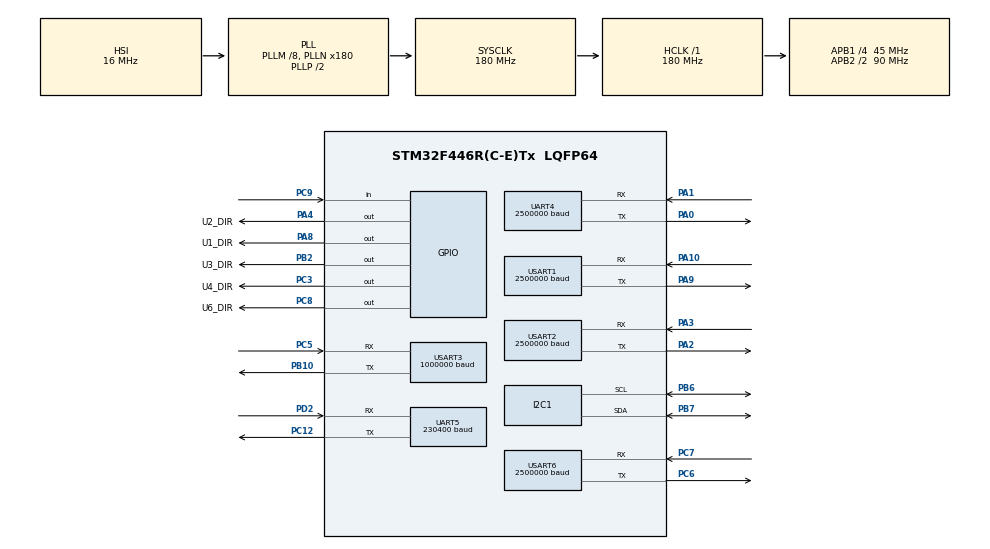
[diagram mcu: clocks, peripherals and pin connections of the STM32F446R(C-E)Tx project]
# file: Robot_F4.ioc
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Dma.Request0=USART3_TX
Dma.Request1=USART3_RX
Dma.Request10=UART4_TX
Dma.Request11=UART4_RX
Dma.Request2=UART5_TX
Dma.Request3=UART5_RX
Dma.Request4=USART2_TX
Dma.Request5=USART2_RX
Dma.Request6=USART1_TX
Dma.Request7=USART1_RX
Dma.Request8=USART6_TX
Dma.Request9=USART6_RX
Dma.UART4_RX.11.Direction=DMA_PERIPH_TO_MEMORY
Dma.UART4_RX.11.FIFOMode=DMA_FIFOMODE_DISABLE
Dma.UART4_RX.11.Instance=DMA1_Stream2
Dma.UART4_RX.11.MemDataAlignment=DMA_MDATAALIGN_BYTE
Dma.UART4_RX.11.MemInc=DMA_MINC_ENABLE
Dma.UART4_RX.11.Mode=DMA_NORMAL
Dma.UART4_RX.11.PeriphDataAlignment=DMA_PDATAALIGN_BYTE
Dma.UART4_RX.11.PeriphInc=DMA_PINC_DISABLE
Dma.UART4_RX.11.Priority=DMA_PRIORITY_LOW
Dma.UART4_TX.10.Direction=DMA_MEMORY_TO_PERIPH
Dma.UART4_TX.10.FIFOMode=DMA_FIFOMODE_DISABLE
Dma.UART4_TX.10.Instance=DMA1_Stream4
Dma.UART4_TX.10.MemDataAlignment=DMA_MDATAALIGN_BYTE
Dma.UART4_TX.10.MemInc=DMA_MINC_ENABLE
Dma.UART4_TX.10.Mode=DMA_NORMAL
Dma.UART4_TX.10.PeriphDataAlignment=DMA_PDATAALIGN_BYTE
Dma.UART4_TX.10.PeriphInc=DMA_PINC_DISABLE
Dma.UART4_TX.10.Priority=DMA_PRIORITY_LOW
Dma.UART5_RX.3.Direction=DMA_PERIPH_TO_MEMORY
Dma.UART5_RX.3.FIFOMode=DMA_FIFOMODE_DISABLE
Dma.UART5_RX.3.Instance=DMA1_Stream0
Dma.UART5_RX.3.MemDataAlignment=DMA_MDATAALIGN_BYTE
Dma.UART5_RX.3.MemInc=DMA_MINC_ENABLE
Dma.UART5_RX.3.Mode=DMA_CIRCULAR
Dma.UART5_RX.3.PeriphDataAlignment=DMA_PDATAALIGN_BYTE
Dma.UART5_RX.3.PeriphInc=DMA_PINC_DISABLE
Dma.UART5_RX.3.Priority=DMA_PRIORITY_LOW
Dma.UART5_TX.2.Direction=DMA_MEMORY_TO_PERIPH
Dma.UART5_TX.2.FIFOMode=DMA_FIFOMODE_DISABLE
Dma.UART5_TX.2.Instance=DMA1_Stream7
Dma.UART5_TX.2.MemDataAlignment=DMA_MDATAALIGN_BYTE
Dma.UART5_TX.2.MemInc=DMA_MINC_ENABLE
Dma.UART5_TX.2.Mode=DMA_NORMAL
Dma.UART5_TX.2.PeriphDataAlignment=DMA_PDATAALIGN_BYTE
Dma.UART5_TX.2.PeriphInc=DMA_PINC_DISABLE
Dma.UART5_TX.2.Priority=DMA_PRIORITY_LOW
Dma.USART1_RX.7.Direction=DMA_PERIPH_TO_MEMORY
Dma.USART1_RX.7.FIFOMode=DMA_FIFOMODE_DISABLE
Dma.USART1_RX.7.Instance=DMA2_Stream2
Dma.USART1_RX.7.MemDataAlignment=DMA_MDATAALIGN_BYTE
Dma.USART1_RX.7.MemInc=DMA_MINC_ENABLE
Dma.USART1_RX.7.Mode=DMA_NORMAL
Dma.USART1_RX.7.PeriphDataAlignment=DMA_PDATAALIGN_BYTE
Dma.USART1_RX.7.PeriphInc=DMA_PINC_DISABLE
Dma.USART1_RX.7.Priority=DMA_PRIORITY_LOW
Dma.USART1_TX.6.Direction=DMA_MEMORY_TO_PERIPH
Dma.USART1_TX.6.FIFOMode=DMA_FIFOMODE_DISABLE
Dma.USART1_TX.6.Instance=DMA2_Stream7
Dma.USART1_TX.6.MemDataAlignment=DMA_MDATAALIGN_BYTE
Dma.USART1_TX.6.MemInc=DMA_MINC_ENABLE
Dma.USART1_TX.6.Mode=DMA_NORMAL
Dma.USART1_TX.6.PeriphDataAlignment=DMA_PDATAALIGN_BYTE
Dma.USART1_TX.6.PeriphInc=DMA_PINC_DISABLE
Dma.USART1_TX.6.Priority=DMA_PRIORITY_LOW
Dma.USART2_RX.5.Direction=DMA_PERIPH_TO_MEMORY
Dma.USART2_RX.5.FIFOMode=DMA_FIFOMODE_DISABLE
Dma.USART2_RX.5.Instance=DMA1_Stream5
Dma.USART2_RX.5.MemDataAlignment=DMA_MDATAALIGN_BYTE
Dma.USART2_RX.5.MemInc=DMA_MINC_ENABLE
Dma.USART2_RX.5.Mode=DMA_NORMAL
Dma.USART2_RX.5.PeriphDataAlignment=DMA_PDATAALIGN_BYTE
Dma.USART2_RX.5.PeriphInc=DMA_PINC_DISABLE
Dma.USART2_RX.5.Priority=DMA_PRIORITY_LOW
Dma.USART2_TX.4.Direction=DMA_MEMORY_TO_PERIPH
Dma.USART2_TX.4.FIFOMode=DMA_FIFOMODE_DISABLE
Dma.USART2_TX.4.Instance=DMA1_Stream6
Dma.USART2_TX.4.MemDataAlignment=DMA_MDATAALIGN_BYTE
Dma.USART2_TX.4.MemInc=DMA_MINC_ENABLE
Dma.USART2_TX.4.Mode=DMA_NORMAL
Dma.USART2_TX.4.PeriphDataAlignment=DMA_PDATAALIGN_BYTE
Dma.USART2_TX.4.PeriphInc=DMA_PINC_DISABLE
Dma.USART2_TX.4.Priority=DMA_PRIORITY_LOW
Dma.USART3_RX.1.Direction=DMA_PERIPH_TO_MEMORY
Dma.USART3_RX.1.FIFOMode=DMA_FIFOMODE_DISABLE
Dma.USART3_RX.1.Instance=DMA1_Stream1
Dma.USART3_RX.1.MemDataAlignment=DMA_MDATAALIGN_BYTE
Dma.USART3_RX.1.MemInc=DMA_MINC_ENABLE
Dma.USART3_RX.1.Mode=DMA_NORMAL
Dma.USART3_RX.1.PeriphDataAlignment=DMA_PDATAALIGN_BYTE
Dma.USART3_RX.1.PeriphInc=DMA_PINC_DISABLE
Dma.USART3_RX.1.Priority=DMA_PRIORITY_LOW
Dma.USART3_TX.0.Direction=DMA_MEMORY_TO_PERIPH
Dma.USART3_TX.0.FIFOMode=DMA_FIFOMODE_DISABLE
Dma.USART3_TX.0.Instance=DMA1_Stream3
Dma.USART3_TX.0.MemDataAlignment=DMA_MDATAALIGN_BYTE
Dma.USART3_TX.0.MemInc=DMA_MINC_ENABLE
Dma.USART3_TX.0.Mode=DMA_NORMAL
Dma.USART3_TX.0.PeriphDataAlignment=DMA_PDATAALIGN_BYTE
Dma.USART3_TX.0.PeriphInc=DMA_PINC_DISABLE
Dma.USART3_TX.0.Priority=DMA_PRIORITY_LOW
Dma.USART6_RX.9.Direction=DMA_PERIPH_TO_MEMORY
Dma.USART6_RX.9.FIFOMode=DMA_FIFOMODE_DISABLE
Dma.USART6_RX.9.Instance=DMA2_Stream1
Dma.USART6_RX.9.MemDataAlignment=DMA_MDATAALIGN_BYTE
Dma.USART6_RX.9.MemInc=DMA_MINC_ENABLE
Dma.USART6_RX.9.Mode=DMA_NORMAL
Dma.USART6_RX.9.PeriphDataAlignment=DMA_PDATAALIGN_BYTE
Dma.USART6_RX.9.PeriphInc=DMA_PINC_DISABLE
Dma.USART6_RX.9.Priority=DMA_PRIORITY_LOW
Dma.USART6_TX.8.Direction=DMA_MEMORY_TO_PERIPH
Dma.USART6_TX.8.FIFOMode=DMA_FIFOMODE_DISABLE
Dma.USART6_TX.8.Instance=DMA2_Stream6
Dma.USART6_TX.8.MemDataAlignment=DMA_MDATAALIGN_BYTE
Dma.USART6_TX.8.MemInc=DMA_MINC_ENABLE
Dma.USART6_TX.8.Mode=DMA_NORMAL
Dma.USART6_TX.8.PeriphDataAlignment=DMA_PDATAALIGN_BYTE
Dma.USART6_TX.8.PeriphInc=DMA_PINC_DISABLE
Dma.USART6_TX.8.Priority=DMA_PRIORITY_LOW
FREERTOS.INCLUDE_vTaskDelayUntil=1
FREERTOS.MEMORY_ALLOCATION=2
FREERTOS.Mutexes01=PCUART,Static,PCUARTControlBlock;DATABUFFER,Static,DATABUFFERControlBlock
FREERTOS.Queues01=UpperLeftLeg_req,16,UARTcmd_t,0,Static,UpperLeftLeg_reqBuffer,UpperLeftLeg_reqControlBlock;LowerRightLeg_req,16,UARTcmd_t,0,Static,LowerRightLeg_reqBuffer,LowerRightLeg_reqControlBlock;HeadAndArms_req,16,UARTcmd_t,0,Static,HeadAndArms_reqBuffer,HeadAndArms_reqControlBlock;UpperRightLeg_req,16,UARTcmd_t,0,Static,UpperRightLeg_reqBuffer,UpperRightLeg_reqControlBlock;LowerLeftLeg_req,16,UARTcmd_t,0,Static,LowerLeftLeg_reqBuffer,LowerLeftLeg_reqControlBlock;BufferWriteQueue,32,TXData_t,0,Static,BufferWriteQueueBuffer,BufferWriteQueueControlBlock
FREERTOS.Tasks01=defaultTask,-3,128,StartDefaultTask,Default,NULL,Static,defaultTaskBuffer,defaultTaskControlBlock;UpperLeftLeg,-1,128,StartUpperLeftLeg,As external,NULL,Static,UpperLeftLegBuffer,UpperLeftLegControlBlock;LowerRightLeg,-1,128,StartLowerRightLeg,As external,NULL,Static,LowerRightLegBuffer,LowerRightLegControlBlock;HeadAndArms,-1,128,StartHeadAndArms,As external,NULL,Static,HeadAndArmsBuffer,HeadAndArmsControlBlock;UpperRightLeg,-1,128,StartUpperRightLeg,As external,NULL,Static,UpperRightLegBuffer,UpperRightLegControlBlock;LowerLeftLeg,-1,128,StartLowerLeftLeg,As external,NULL,Static,LowerLeftLegBuffer,LowerLeftLegControlBlock;IMUTask,0,128,StartIMUTask,As external,NULL,Static,IMUTaskBuffer,IMUTaskControlBlock;CommandTask,1,128,StartCommandTask,As external,NULL,Static,CommandTaskBuffer,CommandTaskControlBlock;RxTask,3,512,StartRxTask,As external,NULL,Static,RxTaskBuffer,RxTaskControlBlock;TxTask,2,512,StartTxTask,As external,NULL,Static,TxTaskBuffer,TxTaskControlBlock;BuffWriterTask,0,128,StartBuffWriterTask,As external,NULL,Static,BuffWriterTaskBuffer,BuffWriterTaskControlBlock;MotorCmdGenTask,0,128,StartMotorCmdGenTask,As external,NULL,Static,MotorCmdGenTaskBuffer,MotorCmdGenTaskControlBlock
I2C1.I2C_Mode=I2C_Fast
Mcu.Family=STM32F4
Mcu.Name=STM32F446R(C-E)Tx
Mcu.Package=LQFP64
NVIC.DMA1_Stream0_IRQn=true\:5\:0\:false\:false\:true\:true\:false
NVIC.DMA1_Stream1_IRQn=true\:5\:0\:false\:false\:true\:true\:false
NVIC.DMA1_Stream2_IRQn=true\:5\:0\:false\:false\:true\:true\:false
NVIC.DMA1_Stream3_IRQn=true\:5\:0\:false\:false\:true\:true\:false
NVIC.DMA1_Stream4_IRQn=true\:5\:0\:false\:false\:true\:true\:false
NVIC.DMA1_Stream5_IRQn=true\:5\:0\:false\:false\:true\:true\:false
NVIC.DMA1_Stream6_IRQn=true\:5\:0\:false\:false\:true\:true\:false
NVIC.DMA1_Stream7_IRQn=true\:5\:0\:false\:false\:true\:true\:false
NVIC.DMA2_Stream1_IRQn=true\:5\:0\:false\:false\:true\:true\:false
NVIC.DMA2_Stream2_IRQn=true\:5\:0\:false\:false\:true\:true\:false
NVIC.DMA2_Stream6_IRQn=true\:5\:0\:false\:false\:true\:true\:false
NVIC.DMA2_Stream7_IRQn=true\:5\:0\:false\:false\:true\:true\:false
NVIC.I2C1_EV_IRQn=true\:5\:0\:false\:false\:true\:true\:true
NVIC.PriorityGroup=NVIC_PRIORITYGROUP_4
NVIC.TIM1_UP_TIM10_IRQn=true\:0\:0\:false\:false\:true\:false\:false
NVIC.TimeBase=TIM1_UP_TIM10_IRQn
NVIC.TimeBaseIP=TIM1
NVIC.UART4_IRQn=true\:5\:0\:false\:false\:true\:true\:true
NVIC.UART5_IRQn=true\:5\:0\:false\:false\:true\:true\:true
NVIC.USART1_IRQn=true\:5\:0\:false\:false\:true\:true\:true
NVIC.USART2_IRQn=true\:5\:0\:false\:false\:true\:true\:true
NVIC.USART3_IRQn=true\:5\:0\:false\:false\:true\:true\:true
NVIC.USART6_IRQn=true\:5\:0\:false\:false\:true\:true\:true
PA0-WKUP.Mode=Asynchronous
PA0-WKUP.Signal=UART4_TX
PA1.Mode=Asynchronous
PA1.Signal=UART4_RX
PA10.Mode=Asynchronous
PA10.Signal=USART1_RX
PA2.Mode=Asynchronous
PA2.Signal=USART2_TX
PA3.Mode=Asynchronous
PA3.Signal=USART2_RX
PA4.GPIO_Label=U2_DIR
PA4.GPIO_Speed=GPIO_SPEED_FREQ_VERY_HIGH
PA4.Signal=GPIO_Output
PA8.GPIO_Label=U1_DIR
PA8.GPIO_Speed=GPIO_SPEED_FREQ_VERY_HIGH
PA8.Signal=GPIO_Output
PA9.Mode=Asynchronous
PA9.Signal=USART1_TX
PB10.Mode=Asynchronous
PB10.Signal=USART3_TX
PB2.GPIO_Label=U3_DIR
PB2.GPIO_Speed=GPIO_SPEED_FREQ_VERY_HIGH
PB2.Signal=GPIO_Output
PB6.Mode=I2C
PB6.Signal=I2C1_SCL
PB7.Mode=I2C
PB7.Signal=I2C1_SDA
PC12.Mode=Asynchronous
PC12.Signal=UART5_TX
PC3.GPIO_Label=U4_DIR
PC3.GPIO_Speed=GPIO_SPEED_FREQ_VERY_HIGH
PC3.Signal=GPIO_Output
PC5.Mode=Asynchronous
PC5.Signal=USART3_RX
PC6.Mode=Asynchronous
PC6.Signal=USART6_TX
PC7.Mode=Asynchronous
PC7.Signal=USART6_RX
PC8.GPIO_Label=U6_DIR
PC8.GPIO_Speed=GPIO_SPEED_FREQ_VERY_HIGH
PC8.Signal=GPIO_Output
PC9.Signal=GPIO_Input
PD2.Mode=Asynchronous
PD2.Signal=UART5_RX
ProjectManager.HeapSize=0x200
ProjectManager.StackSize=0x400
ProjectManager.TargetToolchain=SW4STM32
RCC.AHBFreq_Value=180000000
RCC.APB1CLKDivider=RCC_HCLK_DIV4
RCC.APB1Freq_Value=45000000
RCC.APB1TimFreq_Value=90000000
RCC.APB2CLKDivider=RCC_HCLK_DIV2
RCC.APB2Freq_Value=90000000
RCC.APB2TimFreq_Value=180000000
RCC.CortexFreq_Value=180000000
RCC.HCLKFreq_Value=180000000
RCC.PLLM=8
RCC.PLLN=180
RCC.SYSCLKFreq_VALUE=180000000
RCC.SYSCLKSource=RCC_SYSCLKSOURCE_PLLCLK
RCC.USBFreq_Value=180000000
RCC.VCOOutputFreq_Value=360000000
UART4.BaudRate=2500000
UART4.VirtualMode=Asynchronous
UART5.BaudRate=230400
UART5.VirtualMode=Asynchronous
USART1.BaudRate=2500000
USART1.VirtualMode=VM_ASYNC
USART2.BaudRate=2500000
USART2.VirtualMode=VM_ASYNC
USART3.BaudRate=1000000
USART3.VirtualMode=VM_ASYNC
USART6.BaudRate=2500000
USART6.VirtualMode=VM_ASYNC
VP_FREERTOS_VS_ENABLE.Mode=Enabled
VP_SYS_VS_tim1.Mode=TIM1
board=Robot_F4

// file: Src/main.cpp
/**
  ******************************************************************************
  * @file           : main.c
  * @brief          : Main program body
  ******************************************************************************
  * This notice applies to any and all portions of this file
  * that are not between comment pairs USER CODE BEGIN and
  * USER CODE END. Other portions of this file, whether
  * inserted by the user or by software development tools
  * are owned by their respective copyright owners.
  *
  * Copyright (c) 2018 STMicroelectronics International N.V.
  * All rights reserved.
  *
  * Redistribution and use in source and binary forms, with or without
  * modification, are permitted, provided that the following conditions are met:
  *
  * 1. Redistribution of source code must retain the above copyright notice,
  *    this list of conditions and the following disclaimer.
  * 2. Redistributions in binary form must reproduce the above copyright notice,
  *    this list of conditions and the following disclaimer in the documentation
  *    and/or other materials provided with the distribution.
  * 3. Neither the name of STMicroelectronics nor the names of other
  *    contributors to this software may be used to endorse or promote products
  *    derived from this software without specific written permission.
  * 4. This software, including modifications and/or derivative works of this
  *    software, must execute solely and exclusively on microcontroller or
  *    microprocessor devices manufactured by or for STMicroelectronics.
  * 5. Redistribution and use of this software other than as permitted under
  *    this license is void and will automatically terminate your rights under
  *    this license.
  *
  * THIS SOFTWARE IS PROVIDED BY STMICROELECTRONICS AND CONTRIBUTORS "AS IS"
  * AND ANY EXPRESS, IMPLIED OR STATUTORY WARRANTIES, INCLUDING, BUT NOT
  * LIMITED TO, THE IMPLIED WARRANTIES OF MERCHANTABILITY, FITNESS FOR A
  * PARTICULAR PURPOSE AND NON-INFRINGEMENT OF THIRD PARTY INTELLECTUAL PROPERTY
  * RIGHTS ARE DISCLAIMED TO THE FULLEST EXTENT PERMITTED BY LAW. IN NO EVENT
  * SHALL STMICROELECTRONICS OR CONTRIBUTORS BE LIABLE FOR ANY DIRECT, INDIRECT,
  * INCIDENTAL, SPECIAL, EXEMPLARY, OR CONSEQUENTIAL DAMAGES (INCLUDING, BUT NOT
  * LIMITED TO, PROCUREMENT OF SUBSTITUTE GOODS OR SERVICES; LOSS OF USE, DATA,
  * OR PROFITS; OR BUSINESS INTERRUPTION) HOWEVER CAUSED AND ON ANY THEORY OF
  * LIABILITY, WHETHER IN CONTRACT, STRICT LIABILITY, OR TORT (INCLUDING
  * NEGLIGENCE OR OTHERWISE) ARISING IN ANY WAY OUT OF THE USE OF THIS SOFTWARE,
  * EVEN IF ADVISED OF THE POSSIBILITY OF SUCH DAMAGE.
  *
  ******************************************************************************
  */
#include "main.h"
#include "stm32f4xx_hal.h"
#include "cmsis_os.h"
#include "dma.h"
#include "i2c.h"
#include "usart.h"
#include "gpio.h"

/* USER CODE BEGIN Includes */

#include "SystemConf.h"

/* USER CODE END Includes */

/* USER CODE BEGIN PV */
/* Private variables ---------------------------------------------------------*/

/* USER CODE END PV */

void SystemClock_Config(void);
void MX_FREERTOS_Init(void);

/* USER CODE BEGIN PFP */
/* Private function prototypes -----------------------------------------------*/

/* USER CODE END PFP */

int main(void)
{

  /* MCU Configuration----------------------------------------------------------*/

  /* Reset of all peripherals, Initializes the Flash interface and the Systick. */
  HAL_Init();

  /* Configure the system clock */
  SystemClock_Config();

  /* Initialize all configured peripherals */
  MX_GPIO_Init();
  MX_DMA_Init();
  MX_USART1_UART_Init();
  MX_USART6_UART_Init();
  MX_USART2_UART_Init();
  MX_UART4_Init();
  MX_I2C1_Init();
  MX_USART3_UART_Init();
  MX_UART5_Init();
  /* USER CODE BEGIN 2 */

#if defined(USE_DEBUG_UART)
#pragma "warning: check that the UART configuration in main.cpp is correct!"
  SystemConfDebug_Restart_UARTs();
#endif

  /* USER CODE END 2 */

  /* Call init function for freertos objects (in freertos.c) */
  MX_FREERTOS_Init();

  /* Start scheduler */
  osKernelStart();

  /* We should never get here as control is now taken by the scheduler */

  /* Infinite loop */
  while (1)
  {

  }

}

void SystemClock_Config(void)
{

  RCC_OscInitTypeDef RCC_OscInitStruct;
  RCC_ClkInitTypeDef RCC_ClkInitStruct;

    /**Configure the main internal regulator output voltage
    */
  __HAL_RCC_PWR_CLK_ENABLE();

  __HAL_PWR_VOLTAGESCALING_CONFIG(PWR_REGULATOR_VOLTAGE_SCALE1);

    /**Initializes the CPU, AHB and APB busses clocks
    */
  RCC_OscInitStruct.OscillatorType = RCC_OSCILLATORTYPE_HSI;
  RCC_OscInitStruct.HSIState = RCC_HSI_ON;
  RCC_OscInitStruct.HSICalibrationValue = 16;
  RCC_OscInitStruct.PLL.PLLState = RCC_PLL_ON;
  RCC_OscInitStruct.PLL.PLLSource = RCC_PLLSOURCE_HSI;
  RCC_OscInitStruct.PLL.PLLM = 8;
  RCC_OscInitStruct.PLL.PLLN = 180;
  RCC_OscInitStruct.PLL.PLLP = RCC_PLLP_DIV2;
  RCC_OscInitStruct.PLL.PLLQ = 2;
  RCC_OscInitStruct.PLL.PLLR = 2;
  if (HAL_RCC_OscConfig(&RCC_OscInitStruct) != HAL_OK)
  {
    _Error_Handler(__FILE__, __LINE__);
  }

    /**Activate the Over-Drive mode
    */
  if (HAL_PWREx_EnableOverDrive() != HAL_OK)
  {
    _Error_Handler(__FILE__, __LINE__);
  }

    /**Initializes the CPU, AHB and APB busses clocks
    */
  RCC_ClkInitStruct.ClockType = RCC_CLOCKTYPE_HCLK|RCC_CLOCKTYPE_SYSCLK
                              |RCC_CLOCKTYPE_PCLK1|RCC_CLOCKTYPE_PCLK2;
  RCC_ClkInitStruct.SYSCLKSource = RCC_SYSCLKSOURCE_PLLCLK;
  RCC_ClkInitStruct.AHBCLKDivider = RCC_SYSCLK_DIV1;
  RCC_ClkInitStruct.APB1CLKDivider = RCC_HCLK_DIV4;
  RCC_ClkInitStruct.APB2CLKDivider = RCC_HCLK_DIV2;

  if (HAL_RCC_ClockConfig(&RCC_ClkInitStruct, FLASH_LATENCY_5) != HAL_OK)
  {
    _Error_Handler(__FILE__, __LINE__);
  }

    /**Configure the Systick interrupt time
    */
  HAL_SYSTICK_Config(HAL_RCC_GetHCLKFreq()/1000);

    /**Configure the Systick
    */
  HAL_SYSTICK_CLKSourceConfig(SYSTICK_CLKSOURCE_HCLK);

  /* SysTick_IRQn interrupt configuration */
  HAL_NVIC_SetPriority(SysTick_IRQn, 15, 0);
}

void HAL_TIM_PeriodElapsedCallback(TIM_HandleTypeDef *htim)
{
  if (htim->Instance == TIM1) {
    HAL_IncTick();
  }
}

void _Error_Handler(char *file, int line)
{
  while(1)
  {
  }
}

/************************ (C) COPYRIGHT STMicroelectronics *****END OF FILE****/
